AUTOSAR XML (schema 4-0-3)
package /PATAC/MSM/ComponentTypes
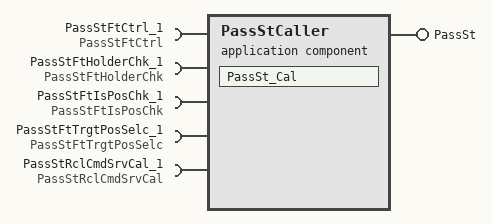
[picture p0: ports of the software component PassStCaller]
  application sw component type PassStCaller
    provide port PassSt: server-com-spec{operation=PassSt/Cal, queue-length=1}, provided-interface=PassSt
    5 x require port:
      PassStFtCtrl_1: client-com-spec=PassStFtCtrl/Cal, required-interface=PassStFtCtrl
      PassStFtHolderChk_1: client-com-spec=PassStFtHolderChk/Cal, required-interface=PassStFtHolderChk
      PassStFtIsPosChk_1: client-com-spec=PassStFtIsPosChk/Cal, required-interface=PassStFtIsPosChk
      PassStFtTrgtPosSelc_1: client-com-spec=PassStFtTrgtPosSelc/Cal, required-interface=PassStFtTrgtPosSelc
      PassStRclCmdSrvCal_1: client-com-spec=PassStRclCmdSrvCal/Cal, required-interface=PassStRclCmdSrvCal
    behavior PassStCaller_InternalBehavior
      operation invoked event OIT_PassSt_Cal_PassSt_Cal: start-on-event=PassSt_Cal, operation=PassSt.Cal
      runnable PassSt_Cal
        5 x sync call, all with timeout=0:
          SC_PassStFtCtrl_1_Cal: operation=PassStFtCtrl_1.Cal
          SC_PassStFtHolderChk_1_Cal: operation=PassStFtHolderChk_1.Cal
          SC_PassStFtIsPosChk_1_Cal: operation=PassStFtIsPosChk_1.Cal
          SC_PassStFtTrgtPosSelc_1_Cal: operation=PassStFtTrgtPosSelc_1.Cal
          SC_PassStRclCmdSrvCal_1_Cal: operation=PassStRclCmdSrvCal_1.Cal
  swc implementation PassStCaller_Implementation: behavior=PassStCaller_InternalBehavior
    code-descriptors:
      code Default: artifact-descriptors=autosar-engineering-object={short-label=Default, category=SWSRC}
package /PATAC/MSM/ModeAdjust/PortInterface
  6 x client server interface:
    PassSt
      operation Cal
    PassStFtCtrl
      operation Cal
    PassStFtHolderChk
      operation Cal
    PassStFtIsPosChk
      operation Cal
    PassStFtTrgtPosSelc
      operation Cal
    PassStRclCmdSrvCal
      operation Cal
